VERSION "dbc-export 1 2025.20.8"

NS_ :

BS_:

BU_: CC EPBR GTW HVP PCS VCFRONT VCRIGHT VCSEC

BO_ 812 CC_logData: 8 CC
 SG_ CC_logIndex M : 0|8@1+ (1,0) [0|255] "" Vector__XXX
 SG_ CC_activeConnectorID m0 : 8|8@1+ (1,0) [0|255] "" Vector__XXX
 SG_ CC_temperature1 m0 : 16|8@1- (1,88) [-40|215] "DegC" Vector__XXX
 SG_ CC_temperature2 m0 : 24|8@1- (1,88) [-40|215] "DegC" Vector__XXX
 SG_ CC_temperature3 m0 : 32|8@1- (1,88) [-40|215] "DegC" Vector__XXX
 SG_ CC_contactor1Closed m0 : 40|2@1+ (1,0) [0|3] "" Vector__XXX
 SG_ CC_contactor2Closed m0 : 42|2@1+ (1,0) [0|3] "" Vector__XXX
 SG_ CC_temperature4 m0 : 44|8@1- (1,88) [-40|215] "DegC" Vector__XXX
 SG_ CC_conn1Current m1 : 8|8@1+ (0.5,0) [0|127] "A" Vector__XXX
 SG_ CC_conn2Current m2 : 8|8@1+ (0.5,0) [0|127] "A" Vector__XXX
 SG_ CC_conn3Current m3 : 8|8@1+ (0.5,0) [0|127] "A" Vector__XXX
 SG_ CC_conn4Current m4 : 8|8@1+ (0.5,0) [0|127] "A" Vector__XXX
 SG_ CC_lifetimei2t m10 : 32|32@1+ (0.1,0) [0|429496729.5] "A2h" Vector__XXX
 SG_ CC_lifetimeCtrCycles m11 : 8|28@1+ (1,0) [0|268435455] "" Vector__XXX
 SG_ CC_lifetimeCtrCyclesLoaded m11 : 36|28@1+ (1,0) [0|268435455] "" Vector__XXX
 SG_ CC_lifetimeAlertCount m12 : 8|28@1+ (1,0) [0|268435455] "" Vector__XXX
 SG_ CC_lifetimeThermalFoldbacks m12 : 36|28@1+ (1,0) [0|268435455] "" Vector__XXX
 SG_ CC_lifetimeAvgStartupTemp m13 : 36|28@1- (0.1,0) [-13421772.8|13421772.7] "degC" Vector__XXX

BO_ 2024 EPBR_info: 8 EPBR
 SG_ EPBR_infoIndex M : 0|8@1+ (1,0) [0|255] "" Vector__XXX
 SG_ EPBR_infoBuildType m10 : 8|3@1+ (1,0) [0|7] "" Vector__XXX
 SG_ EPBR_infoBuildConfigId m10 : 16|16@1+ (1,0) [0|65535] "" Vector__XXX
 SG_ EPBR_infoHardwareId m10 : 32|16@1+ (1,0) [0|65535] "" Vector__XXX
 SG_ EPBR_infoComponentId m10 : 48|16@1+ (1,0) [0|65535] "" Vector__XXX
 SG_ EPBR_infoPcbaId m11 : 8|8@1+ (1,0) [0|255] "" Vector__XXX
 SG_ EPBR_infoAssemblyId m11 : 16|8@1+ (1,0) [0|254] "" Vector__XXX
 SG_ EPBR_infoUsageId m11 : 24|16@1+ (1,0) [0|65535] "" Vector__XXX
 SG_ EPBR_infoSubUsageId m11 : 40|16@1+ (1,0) [0|65535] "" Vector__XXX
 SG_ EPBR_infoAppCrc m13 : 8|32@1+ (1,0) [0|4294967295] "" Vector__XXX
 SG_ EPBR_infoAppGitHash m17 : 8|56@1+ (1,0) [0|7.20575940379e+16] "" Vector__XXX
 SG_ EPBR_infoBootGitHash m18 : 8|56@1+ (1,0) [0|7.20575940379e+16] "" Vector__XXX
 SG_ EPBR_infoPlatformType m19 : 8|8@1+ (1,0) [0|255] "" Vector__XXX
 SG_ EPBR_infoBootUdsProtoVersion m20 : 8|16@1+ (1,0) [0|65535] "" Vector__XXX
 SG_ EPBR_infoBootCrc m20 : 24|32@1+ (1,0) [0|4294967295] "" Vector__XXX

BO_ 1914 HVP_log1hz: 8 HVP
 SG_ HVP_log1HzIndex M : 0|3@1+ (1,0) [0|7] "" Vector__XXX
 SG_ HVP_bmbAsicType m0 : 3|2@1+ (1,0) [0|3] "" Vector__XXX
 SG_ HVP_shuntCurrentAuxLog m0 : 8|24@1- (0.001,0) [-8388.607|8388.607] "A" Vector__XXX
 SG_ HVP_pyroSquibResistance m0 : 32|16@1+ (0.001,0) [0|65.534] "Ohm" Vector__XXX
 SG_ HVP_shuntAsicChipXCoordinate m0 : 48|8@1+ (1,0) [0|255] "" Vector__XXX
 SG_ HVP_shuntAsicChipYCoordinate m0 : 56|8@1+ (1,0) [0|255] "" Vector__XXX
 SG_ HVP_hvilCalType m1 : 3|2@1+ (1,0) [0|3] "" Vector__XXX
 SG_ HVP_gpioPcsDcdcPwmEnable m1 : 5|1@1+ (1,0) [0|1] "" Vector__XXX
 SG_ HVP_gpioPcsChargePwmEnable m1 : 6|1@1+ (1,0) [0|1] "" Vector__XXX
 SG_ HVP_gpioPcsEnable m1 : 7|1@1+ (1,0) [0|1] "" Vector__XXX
 SG_ HVP_shuntAsicChipWaferNumber m1 : 8|8@1+ (1,0) [0|255] "" Vector__XXX
 SG_ HVP_energyReserveMin m1 : 16|16@1- (0.001,0) [-32.768|32.767] "V" Vector__XXX
 SG_ HVP_energyReserveMax m1 : 32|16@1- (0.001,0) [-32.768|32.767] "V" Vector__XXX
 SG_ HVP_energyReserveAvg m1 : 48|16@1- (0.001,0) [-32.768|32.767] "V" Vector__XXX

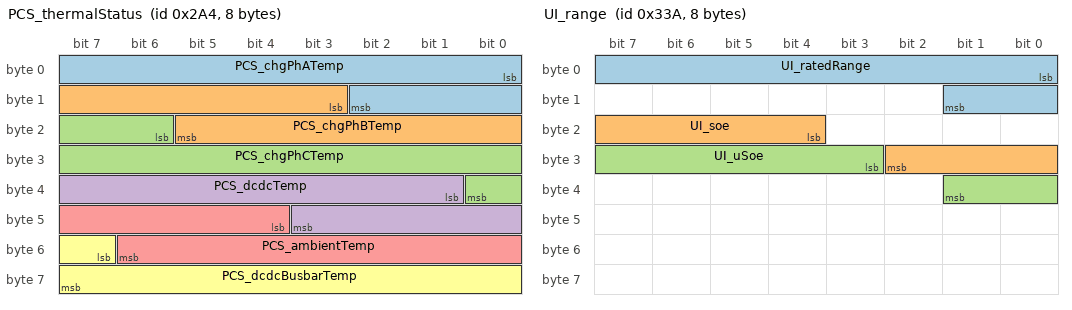
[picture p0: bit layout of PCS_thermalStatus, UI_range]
BO_ 676 PCS_thermalStatus: 8 PCS
 SG_ PCS_chgPhATemp : 0|11@1- (0.1,40) [-62.4|142.3] "C" Vector__XXX
 SG_ PCS_chgPhBTemp : 11|11@1- (0.1,40) [-62.4|142.3] "C" Vector__XXX
 SG_ PCS_chgPhCTemp : 22|11@1- (0.1,40) [-62.4|142.3] "C" Vector__XXX
 SG_ PCS_dcdcTemp : 33|11@1- (0.1,40) [-62.4|142.3] "C" Vector__XXX
 SG_ PCS_ambientTemp : 44|11@1- (0.1,40) [-62.4|142.3] "C" Vector__XXX
 SG_ PCS_dcdcBusbarTemp : 55|9@1+ (0.2935421,0) [0|149.706471] "C" Vector__XXX

BO_ 826 UI_range: 8 GTW
 SG_ UI_ratedRange : 0|10@1+ (1,0) [0|1023] "mi" Vector__XXX
 SG_ UI_soe : 20|7@1+ (1,0) [0|127] "%" Vector__XXX
 SG_ UI_uSoe : 27|7@1+ (1,0) [0|127] "%" Vector__XXX

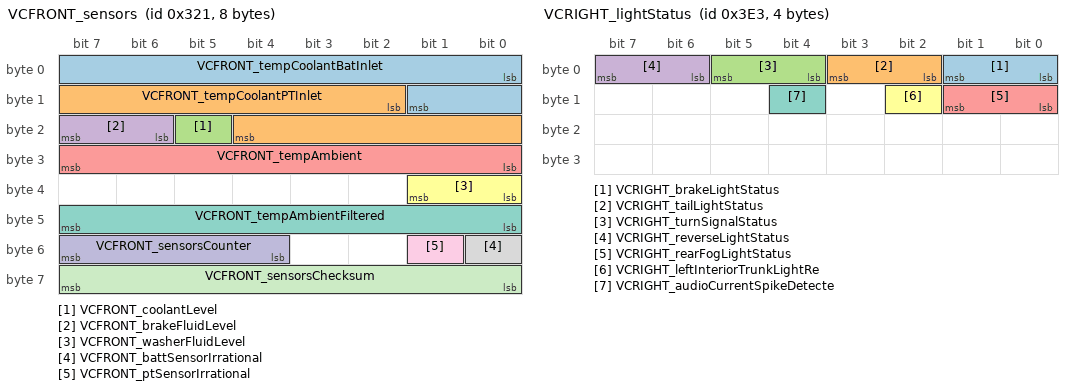
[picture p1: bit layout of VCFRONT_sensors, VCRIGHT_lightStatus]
BO_ 801 VCFRONT_sensors: 8 VCFRONT
 SG_ VCFRONT_tempCoolantBatInlet : 0|10@1+ (0.125,-40) [-40|85] "degC" Vector__XXX
 SG_ VCFRONT_tempCoolantPTInlet : 10|11@1+ (0.125,-40) [-40|200] "degC" Vector__XXX
 SG_ VCFRONT_coolantLevel : 21|1@1+ (1,0) [0|1] "" Vector__XXX
 SG_ VCFRONT_brakeFluidLevel : 22|2@1+ (1,0) [1|3] "" Vector__XXX
 SG_ VCFRONT_tempAmbient : 24|8@1+ (0.5,-40) [-39.5|80] "degC" Vector__XXX
 SG_ VCFRONT_washerFluidLevel : 32|2@1+ (1,0) [1|3] "" Vector__XXX
 SG_ VCFRONT_tempAmbientFiltered : 40|8@1+ (0.5,-40) [-39.5|80] "degC" Vector__XXX
 SG_ VCFRONT_battSensorIrrational : 48|1@1+ (1,0) [0|1] "" Vector__XXX
 SG_ VCFRONT_ptSensorIrrational : 49|1@1+ (1,0) [0|1] "" Vector__XXX
 SG_ VCFRONT_sensorsCounter : 52|4@1+ (1,0) [0|15] "" Vector__XXX
 SG_ VCFRONT_sensorsChecksum : 56|8@1+ (1,0) [0|255] "" Vector__XXX

BO_ 1349 VCFRONT_systemStatus: 8 VCFRONT
 SG_ VCFRONT_systemStatusMuxIndex M : 0|2@1+ (1,0) [0|3] "" Vector__XXX
 SG_ VCFRONT_systemStatusCounter : 52|4@1+ (1,0) [0|15] "" Vector__XXX
 SG_ VCFRONT_systemStatusChecksum : 56|8@1+ (1,0) [0|255] "" Vector__XXX
 SG_ VCFRONT_loadShedReason m1 : 3|9@1+ (1,0) [0|511] "" Vector__XXX
 SG_ VCFRONT_VCRightEFuseLoadShedStag m1 : 12|5@1+ (1,0) [0|31] "" Vector__XXX
 SG_ VCFRONT_VCLeftEFuseLoadShedStage m1 : 20|5@1+ (1,0) [0|31] "" Vector__XXX
 SG_ VCFRONT_DCDCSaturationLoadShedSt m1 : 28|5@1+ (1,0) [0|31] "" Vector__XXX
 SG_ VCFRONT_vehicleLoadShedStage m1 : 36|2@1+ (1,0) [0|3] "" Vector__XXX
 SG_ VCFRONT_HVFaultVehicleLoadShedRe m1 : 38|1@1+ (1,0) [0|1] "" Vector__XXX
 SG_ VCFRONT_postCrashVehicleLoadShed m1 : 39|1@1+ (1,0) [0|1] "" Vector__XXX
 SG_ VCFRONT_HVFaultVehicleLoadShedAc m1 : 40|1@1+ (1,0) [0|1] "" Vector__XXX
 SG_ VCFRONT_factoryVehicleLoadShedAc m1 : 41|1@1+ (1,0) [0|1] "" Vector__XXX
 SG_ VCFRONT_anyVehicleLoadShedActive m1 : 42|1@1+ (1,0) [0|1] "" Vector__XXX
 SG_ VCFRONT_DIVehLoadShedActive m1 : 43|1@1+ (1,0) [0|1] "" Vector__XXX
 SG_ VCFRONT_HVFaultLoadShedStateDBG m1 : 44|2@1+ (1,0) [0|3] "" Vector__XXX
 SG_ VCFRONT_LVUnhealthyVehicleLoadSh m1 : 46|1@1+ (1,0) [0|1] "" Vector__XXX
 SG_ VCFRONT_loadShedStsCondenserFan m2 : 3|1@1+ (1,0) [0|1] "" Vector__XXX
 SG_ VCFRONT_loadShedStsPTPump m2 : 6|1@1+ (1,0) [0|1] "" Vector__XXX
 SG_ VCFRONT_loadShedMCUAudio m2 : 10|1@1+ (1,0) [0|1] "" Vector__XXX
 SG_ VCFRONT_loadShedHVDownTriggerDBG m2 : 11|1@1+ (1,0) [0|1] "" Vector__XXX
 SG_ VCFRONT_loadShedPCSSatTriggerDBG m2 : 12|1@1+ (1,0) [0|1] "" Vector__XXX
 SG_ VCFRONT_loadShedStsBatteryPump m2 : 13|1@1+ (1,0) [0|1] "" Vector__XXX
 SG_ VCFRONT_loadShedStsAPGlassHeater m2 : 14|1@1+ (1,0) [0|1] "" Vector__XXX
 SG_ VCFRONT_loadShedStsMCUGraphics m2 : 15|1@1+ (1,0) [0|1] "" Vector__XXX
 SG_ VCFRONT_IBSCurrentRMS_loadShed m2 : 16|7@1+ (0.05,0) [0|6.35] "A" Vector__XXX
 SG_ VCFRONT_loadShedAhLeakyBktCntDBG m2 : 23|9@1+ (0.001,0) [0|0.511] "Ah" Vector__XXX
 SG_ VCFRONT_loadShedPcs m2 : 33|1@1+ (1,0) [0|1] "" Vector__XXX
 SG_ VCFRONT_loadShedGTWDownstrmRails m2 : 35|1@1+ (1,0) [0|1] "" Vector__XXX
 SG_ VCFRONT_loadShedPCSMIATriggerDBG m2 : 36|1@1+ (1,0) [0|1] "" Vector__XXX
 SG_ VCFRONT_loadShedTAS m2 : 37|1@1+ (1,0) [0|1] "" Vector__XXX
 SG_ VCFRONT_loadShedBackStopBktCntDB m2 : 38|5@1+ (0.05,0) [0|1.55] "Ah" Vector__XXX
 SG_ VCFRONT_loadShedPCSLeakyBktCtDBG m2 : 44|6@1+ (100,0) [0|6300] "mV" Vector__XXX
 SG_ VCFRONT_loadShedUI m2 : 50|1@1+ (1,0) [0|1] "" Vector__XXX
 SG_ VCFRONT_loadShedAutoPilot m2 : 51|1@1+ (1,0) [0|1] "" Vector__XXX

BO_ 995 VCRIGHT_lightStatus: 4 VCRIGHT
 SG_ VCRIGHT_brakeLightStatus : 0|2@1+ (1,0) [0|2] "" Vector__XXX
 SG_ VCRIGHT_tailLightStatus : 2|2@1+ (1,0) [0|2] "" Vector__XXX
 SG_ VCRIGHT_turnSignalStatus : 4|2@1+ (1,0) [0|2] "" Vector__XXX
 SG_ VCRIGHT_reverseLightStatus : 6|2@1+ (1,0) [0|2] "" Vector__XXX
 SG_ VCRIGHT_rearFogLightStatus : 8|2@1+ (1,0) [0|2] "" Vector__XXX
 SG_ VCRIGHT_leftInteriorTrunkLightRe : 10|1@1+ (1,0) [0|1] "" Vector__XXX
 SG_ VCRIGHT_audioCurrentSpikeDetecte : 12|1@1+ (1,0) [0|1] "" Vector__XXX

BO_ 1066 VCSEC_TPMSConnectionData: 8 VCSEC
 SG_ VCSEC_TPMSSensorState0 : 0|3@1+ (1,0) [0|7] "" Vector__XXX
 SG_ VCSEC_TPMSRSSI0 : 3|7@1+ (1,-127) [-127|0] "dBm" Vector__XXX
 SG_ VCSEC_TPMSConnectionTypeCurrent0 : 10|2@1+ (1,0) [0|3] "" Vector__XXX
 SG_ VCSEC_TPMSConnectionTypeDesired0 : 12|2@1+ (1,0) [0|3] "" Vector__XXX
 SG_ VCSEC_TPMSSensorState1 : 14|3@1+ (1,0) [0|7] "" Vector__XXX
 SG_ VCSEC_TPMSRSSI1 : 17|7@1+ (1,-127) [-127|0] "dBm" Vector__XXX
 SG_ VCSEC_TPMSConnectionTypeCurrent1 : 24|2@1+ (1,0) [0|3] "" Vector__XXX
 SG_ VCSEC_TPMSConnectionTypeDesired1 : 26|2@1+ (1,0) [0|3] "" Vector__XXX
 SG_ VCSEC_TPMSSensorState2 : 28|3@1+ (1,0) [0|7] "" Vector__XXX
 SG_ VCSEC_TPMSRSSI2 : 31|7@1+ (1,-127) [-127|0] "dBm" Vector__XXX
 SG_ VCSEC_TPMSConnectionTypeCurrent2 : 38|2@1+ (1,0) [0|3] "" Vector__XXX
 SG_ VCSEC_TPMSConnectionTypeDesired2 : 40|2@1+ (1,0) [0|3] "" Vector__XXX
 SG_ VCSEC_TPMSSensorState3 : 42|3@1+ (1,0) [0|7] "" Vector__XXX
 SG_ VCSEC_TPMSRSSI3 : 45|7@1+ (1,-127) [-127|0] "dBm" Vector__XXX
 SG_ VCSEC_TPMSConnectionTypeCurrent3 : 52|2@1+ (1,0) [0|3] "" Vector__XXX
 SG_ VCSEC_TPMSConnectionTypeDesired3 : 54|2@1+ (1,0) [0|3] "" Vector__XXX
 SG_ VCSEC_TPMSSensorPresence0 : 56|2@1+ (1,0) [0|3] "" Vector__XXX
 SG_ VCSEC_TPMSSensorPresence1 : 58|2@1+ (1,0) [0|3] "" Vector__XXX
 SG_ VCSEC_TPMSSensorPresence2 : 60|2@1+ (1,0) [0|3] "" Vector__XXX
 SG_ VCSEC_TPMSSensorPresence3 : 62|2@1+ (1,0) [0|3] "" Vector__XXX

BO_TX_BU_ 812 : CC;
BO_TX_BU_ 2024 : EPBR;
BO_TX_BU_ 1914 : HVP;
BO_TX_BU_ 676 : PCS;
BO_TX_BU_ 826 : GTW;
BO_TX_BU_ 801 : VCFRONT;
BO_TX_BU_ 1349 : VCFRONT;
BO_TX_BU_ 995 : VCRIGHT;
BO_TX_BU_ 1066 : VCSEC;

CM_ "Tesla Bayberry CAN bus database; bus VEH (vehicle CAN); firmware 2025.20.8. Decoded CAN signal definitions (layout, scaling, units, value tables).";
CM_ BU_ CC "Charge cable controller";
CM_ BU_ EPBR "Right electric parking brake";
CM_ BU_ GTW "Gateway";
CM_ BU_ HVP "High-voltage processor (pack contactor and isolation controller)";
CM_ BU_ PCS "Power conversion system (on-board charger and DC-DC converter)";
CM_ BU_ VCFRONT "Front body controller";
CM_ BU_ VCRIGHT "Right body controller";
CM_ BU_ VCSEC "Vehicle security controller";
CM_ BO_ 812 "Charge cable controller message: log data; frame length from the layout, not yet observed on a vehicle bus";
CM_ SG_ 812 CC_logIndex "Charge cable controller: log index";
CM_ SG_ 812 CC_activeConnectorID "Site identifier of active charge connector";
CM_ SG_ 812 CC_temperature1 "Charge cable vehicle connector temperature";
CM_ SG_ 812 CC_temperature2 "Charge cable vehicle connector temperature";
CM_ SG_ 812 CC_temperature3 "Charge cable vehicle connector temperature";
CM_ SG_ 812 CC_contactor1Closed "State of contactor 1 in wall connector";
CM_ SG_ 812 CC_contactor2Closed "State of contactor 1 in wall connector";
CM_ SG_ 812 CC_temperature4 "Charge cable vehicle connector temperature";
CM_ SG_ 812 CC_conn1Current "AC current on connector 1 in wall charger load sharing group; raw 255 = signal not available (SNA)";
CM_ SG_ 812 CC_conn2Current "AC current on connector 2 in wall charger load sharing group; raw 255 = signal not available (SNA)";
CM_ SG_ 812 CC_conn3Current "AC current on connector 3 in wall charger load sharing group; raw 255 = signal not available (SNA)";
CM_ SG_ 812 CC_conn4Current "AC current on connector 4 in wall charger load sharing group; raw 255 = signal not available (SNA)";
CM_ SG_ 812 CC_lifetimei2t "Charge cable controller: lifetimei2t";
CM_ SG_ 812 CC_lifetimeCtrCycles "Charge cable controller: lifetime ctr cycles";
CM_ SG_ 812 CC_lifetimeCtrCyclesLoaded "Charge cable controller: lifetime ctr cycles loaded";
CM_ SG_ 812 CC_lifetimeAlertCount "Charge cable controller: lifetime alert count";
CM_ SG_ 812 CC_lifetimeThermalFoldbacks "Charge cable controller: lifetime thermal foldbacks";
CM_ SG_ 812 CC_lifetimeAvgStartupTemp "Charge cable controller: lifetime avg startup temp";
CM_ BO_ 2024 "Right electric parking brake message: info; frame length observed on a vehicle bus";
CM_ SG_ 2024 EPBR_infoIndex "Right electric parking brake: info index";
CM_ SG_ 2024 EPBR_infoBuildType "Right electric parking brake: info build type";
CM_ SG_ 2024 EPBR_infoBuildConfigId "Right electric parking brake: info build config id";
CM_ SG_ 2024 EPBR_infoHardwareId "Right electric parking brake: info hardware id";
CM_ SG_ 2024 EPBR_infoComponentId "Right electric parking brake: info component id";
CM_ SG_ 2024 EPBR_infoPcbaId "Right electric parking brake: info pcba id";
CM_ SG_ 2024 EPBR_infoAssemblyId "Right electric parking brake: info assembly id; raw 255 = signal not available (SNA)";
CM_ SG_ 2024 EPBR_infoUsageId "Right electric parking brake: info usage id";
CM_ SG_ 2024 EPBR_infoSubUsageId "Right electric parking brake: info sub usage id";
CM_ SG_ 2024 EPBR_infoAppCrc "Right electric parking brake: info app crc";
CM_ SG_ 2024 EPBR_infoAppGitHash "Right electric parking brake: info app git hash";
CM_ SG_ 2024 EPBR_infoBootGitHash "Right electric parking brake: info boot git hash";
CM_ SG_ 2024 EPBR_infoPlatformType "Right electric parking brake: info platform type";
CM_ SG_ 2024 EPBR_infoBootUdsProtoVersion "Right electric parking brake: info boot uds proto version";
CM_ SG_ 2024 EPBR_infoBootCrc "Right electric parking brake: info boot crc";
CM_ BO_ 1914 "High-voltage processor (pack contactor and isolation controller) message: log1hz; frame length observed on a vehicle bus";
CM_ SG_ 1914 HVP_log1HzIndex "High-voltage processor (pack contactor and isolation controller): log1 hz index";
CM_ SG_ 1914 HVP_bmbAsicType "The BMB Asic type being used by this battery pack for reading brick data";
CM_ SG_ 1914 HVP_shuntCurrentAuxLog "High-voltage processor (pack contactor and isolation controller): shunt current aux log";
CM_ SG_ 1914 HVP_pyroSquibResistance "The pyro resistance measured on attempt to close contactor or by the Pyro selftest; raw 65535 = signal not available (SNA)";
CM_ SG_ 1914 HVP_shuntAsicChipXCoordinate "High-voltage processor (pack contactor and isolation controller): shunt asic chip x coordinate";
CM_ SG_ 1914 HVP_shuntAsicChipYCoordinate "High-voltage processor (pack contactor and isolation controller): shunt asic chip y coordinate";
CM_ SG_ 1914 HVP_hvilCalType "High-voltage processor (pack contactor and isolation controller): hvil cal type";
CM_ SG_ 1914 HVP_gpioPcsDcdcPwmEnable "High-voltage processor (pack contactor and isolation controller): gpio pcs dcdc pwm enable";
CM_ SG_ 1914 HVP_gpioPcsChargePwmEnable "High-voltage processor (pack contactor and isolation controller): gpio pcs charge pwm enable";
CM_ SG_ 1914 HVP_gpioPcsEnable "HVP GPIO control for PCS logic power enable line";
CM_ SG_ 1914 HVP_shuntAsicChipWaferNumber "High-voltage processor (pack contactor and isolation controller): shunt asic chip wafer number";
CM_ SG_ 1914 HVP_energyReserveMin "a lowest energy reserve value measured over sliding window";
CM_ SG_ 1914 HVP_energyReserveMax "a highest energy reserve value measured over sliding window";
CM_ SG_ 1914 HVP_energyReserveAvg "an average energy reserve value measured over sliding window";
CM_ BO_ 676 "Power conversion system (on-board charger and DC-DC converter) message: thermal status; frame length observed on a vehicle bus";
CM_ SG_ 676 PCS_chgPhATemp "Sensed temperature of AC charger phase A; raw 1025 = signal not available (SNA)";
CM_ SG_ 676 PCS_chgPhBTemp "Sensed temperature of AC charger phase B; raw 1025 = signal not available (SNA)";
CM_ SG_ 676 PCS_chgPhCTemp "Sensed temperature of AC charger phase C; raw 1025 = signal not available (SNA)";
CM_ SG_ 676 PCS_dcdcTemp "Sensed temperature of DCDC; raw 1025 = signal not available (SNA)";
CM_ SG_ 676 PCS_ambientTemp "Ambient temperature sensed by the PCS; raw 1025 = signal not available (SNA)";
CM_ SG_ 676 PCS_dcdcBusbarTemp "Sensed temperature of DCDC busbar; raw 511 = signal not available (SNA)";
CM_ BO_ 826 "Touchscreen user interface computer message: range; forwarded onto this bus by the gateway; frame length observed on a vehicle bus";
CM_ SG_ 826 UI_ratedRange "Rated range in miles";
CM_ SG_ 826 UI_soe "State of energy";
CM_ SG_ 826 UI_uSoe "Usable state of energy";
CM_ BO_ 801 "Front body controller message: sensors; frame length observed on a vehicle bus";
CM_ SG_ 801 VCFRONT_tempCoolantBatInlet "Battery measured inlet coolant temperature; raw 1023 = signal not available (SNA)";
CM_ SG_ 801 VCFRONT_tempCoolantPTInlet "Powertrain measured inlet coolant temperature; raw 2047 = signal not available (SNA)";
CM_ SG_ 801 VCFRONT_coolantLevel "Front body controller: coolant level";
CM_ SG_ 801 VCFRONT_brakeFluidLevel "Reports detected brake fluid level at the fluid reservoir; raw 0 = signal not available (SNA)";
CM_ SG_ 801 VCFRONT_tempAmbient "Front body controller: temp ambient; raw 0 = signal not available (SNA)";
CM_ SG_ 801 VCFRONT_washerFluidLevel "Indicates that the sensor has detected low windshield washer fluid; raw 0 = signal not available (SNA)";
CM_ SG_ 801 VCFRONT_tempAmbientFiltered "Filtered ambient temperature based on vehicle speed; raw 0 = signal not available (SNA)";
CM_ SG_ 801 VCFRONT_battSensorIrrational "Front body controller: batt sensor irrational";
CM_ SG_ 801 VCFRONT_ptSensorIrrational "Front body controller: pt sensor irrational";
CM_ SG_ 801 VCFRONT_sensorsCounter "Front body controller: sensors counter";
CM_ SG_ 801 VCFRONT_sensorsChecksum "Front body controller: sensors checksum";
CM_ BO_ 1349 "Front body controller message: system status; frame length observed on a vehicle bus";
CM_ SG_ 1349 VCFRONT_systemStatusMuxIndex "Front body controller: system status mux index";
CM_ SG_ 1349 VCFRONT_systemStatusCounter "Front body controller: system status counter";
CM_ SG_ 1349 VCFRONT_systemStatusChecksum "Front body controller: system status checksum";
CM_ SG_ 1349 VCFRONT_loadShedReason "Front body controller: load shed reason";
CM_ SG_ 1349 VCFRONT_VCRightEFuseLoadShedStag "Front body controller: VC right e fuse load shed stage";
CM_ SG_ 1349 VCFRONT_VCLeftEFuseLoadShedStage "Front body controller: VC left e fuse load shed stage";
CM_ SG_ 1349 VCFRONT_DCDCSaturationLoadShedSt "Front body controller: DCDC saturation load shed stage";
CM_ SG_ 1349 VCFRONT_vehicleLoadShedStage "Front body controller: vehicle load shed stage";
CM_ SG_ 1349 VCFRONT_HVFaultVehicleLoadShedRe "Front body controller: HV fault vehicle load shed request";
CM_ SG_ 1349 VCFRONT_postCrashVehicleLoadShed "Front body controller: post crash vehicle load shed active";
CM_ SG_ 1349 VCFRONT_HVFaultVehicleLoadShedAc "Front body controller: HV fault vehicle load shed active";
CM_ SG_ 1349 VCFRONT_factoryVehicleLoadShedAc "Indicates that vehicle is factory load shedding";
CM_ SG_ 1349 VCFRONT_anyVehicleLoadShedActive "Front body controller: any vehicle load shed active";
CM_ SG_ 1349 VCFRONT_DIVehLoadShedActive "Front body controller: DI veh load shed active";
CM_ SG_ 1349 VCFRONT_HVFaultLoadShedStateDBG "Front body controller: HV fault load shed state DBG";
CM_ SG_ 1349 VCFRONT_LVUnhealthyVehicleLoadSh "Front body controller: LV unhealthy vehicle load shed active";
CM_ SG_ 1349 VCFRONT_loadShedStsCondenserFan "Front body controller: load shed sts condenser fan";
CM_ SG_ 1349 VCFRONT_loadShedStsPTPump "Front body controller: load shed sts PT pump";
CM_ SG_ 1349 VCFRONT_loadShedMCUAudio "Front body controller: load shed MCU audio";
CM_ SG_ 1349 VCFRONT_loadShedHVDownTriggerDBG "Front body controller: load shed HV down trigger DBG";
CM_ SG_ 1349 VCFRONT_loadShedPCSSatTriggerDBG "Front body controller: load shed PCS sat trigger DBG";
CM_ SG_ 1349 VCFRONT_loadShedStsBatteryPump "Front body controller: load shed sts battery pump";
CM_ SG_ 1349 VCFRONT_loadShedStsAPGlassHeater "Front body controller: load shed sts AP glass heater";
CM_ SG_ 1349 VCFRONT_loadShedStsMCUGraphics "Front body controller: load shed sts MCU graphics";
CM_ SG_ 1349 VCFRONT_IBSCurrentRMS_loadShed "Front body controller: IBS current RMS load shed";
CM_ SG_ 1349 VCFRONT_loadShedAhLeakyBktCntDBG "Front body controller: load shed ah leaky bkt cnt DBG";
CM_ SG_ 1349 VCFRONT_loadShedPcs "Front body controller: load shed pcs";
CM_ SG_ 1349 VCFRONT_loadShedGTWDownstrmRails "Front body controller: load shed GTW downstrm rails";
CM_ SG_ 1349 VCFRONT_loadShedPCSMIATriggerDBG "Front body controller: load shed PCSMIA trigger DBG";
CM_ SG_ 1349 VCFRONT_loadShedTAS "Front body controller: load shed TAS";
CM_ SG_ 1349 VCFRONT_loadShedBackStopBktCntDB "Front body controller: load shed back stop bkt cnt DBG";
CM_ SG_ 1349 VCFRONT_loadShedPCSLeakyBktCtDBG "Front body controller: load shed PCS leaky bkt ct DBG";
CM_ SG_ 1349 VCFRONT_loadShedUI "Front body controller: load shed UI";
CM_ SG_ 1349 VCFRONT_loadShedAutoPilot "Front body controller: load shed auto pilot";
CM_ BO_ 995 "Right body controller message: light status; frame length observed on a vehicle bus";
CM_ SG_ 995 VCRIGHT_brakeLightStatus "Status of rear right brake light source; raw 3 = signal not available (SNA)";
CM_ SG_ 995 VCRIGHT_tailLightStatus "Status of right tail (rear position) light source; raw 3 = signal not available (SNA)";
CM_ SG_ 995 VCRIGHT_turnSignalStatus "Status of rear right turn signal light source; raw 3 = signal not available (SNA)";
CM_ SG_ 995 VCRIGHT_reverseLightStatus "Status of the reverse light source(s); raw 3 = signal not available (SNA)";
CM_ SG_ 995 VCRIGHT_rearFogLightStatus "The desired on/off state of the rear fog light source(s); raw 3 = signal not available (SNA)";
CM_ SG_ 995 VCRIGHT_leftInteriorTrunkLightRe "Right body controller: left interior trunk light req";
CM_ SG_ 995 VCRIGHT_audioCurrentSpikeDetecte "Right body controller: audio current spike detected";
CM_ BO_ 1066 "Vehicle security controller message: TPMS connection data; frame length from the layout, not yet observed on a vehicle bus";
CM_ SG_ 1066 VCSEC_TPMSSensorState0 "Indicates the sensors pairing/connectivity status";
CM_ SG_ 1066 VCSEC_TPMSRSSI0 "Received Signal Strength Index reported by sensor.";
CM_ SG_ 1066 VCSEC_TPMSConnectionTypeCurrent0 "Vehicle security controller: TPMS connection type current0";
CM_ SG_ 1066 VCSEC_TPMSConnectionTypeDesired0 "Vehicle security controller: TPMS connection type desired0";
CM_ SG_ 1066 VCSEC_TPMSSensorState1 "Indicates the sensors pairing/connectivity status";
CM_ SG_ 1066 VCSEC_TPMSRSSI1 "Received Signal Strength Index reported by sensor.";
CM_ SG_ 1066 VCSEC_TPMSConnectionTypeCurrent1 "Vehicle security controller: TPMS connection type current1";
CM_ SG_ 1066 VCSEC_TPMSConnectionTypeDesired1 "Vehicle security controller: TPMS connection type desired1";
CM_ SG_ 1066 VCSEC_TPMSSensorState2 "Indicates the sensors pairing/connectivity status";
CM_ SG_ 1066 VCSEC_TPMSRSSI2 "Received Signal Strength Index reported by sensor.";
CM_ SG_ 1066 VCSEC_TPMSConnectionTypeCurrent2 "Vehicle security controller: TPMS connection type current2";
CM_ SG_ 1066 VCSEC_TPMSConnectionTypeDesired2 "Vehicle security controller: TPMS connection type desired2";
CM_ SG_ 1066 VCSEC_TPMSSensorState3 "Indicates the sensors pairing/connectivity status";
CM_ SG_ 1066 VCSEC_TPMSRSSI3 "Received Signal Strength Index reported by sensor.";
CM_ SG_ 1066 VCSEC_TPMSConnectionTypeCurrent3 "Vehicle security controller: TPMS connection type current3";
CM_ SG_ 1066 VCSEC_TPMSConnectionTypeDesired3 "Vehicle security controller: TPMS connection type desired3";
CM_ SG_ 1066 VCSEC_TPMSSensorPresence0 "Indicates the sensors detection status";
CM_ SG_ 1066 VCSEC_TPMSSensorPresence1 "Indicates the sensors detection status";
CM_ SG_ 1066 VCSEC_TPMSSensorPresence2 "Indicates the sensors detection status";
CM_ SG_ 1066 VCSEC_TPMSSensorPresence3 "Indicates the sensors detection status";
BA_DEF_ "BusType" STRING;
BA_DEF_ "DBName" STRING;
BA_DEF_ "Baudrate" INT 0 1000000;
BA_DEF_ "BaudrateCANFD" INT 0 16000000;
BA_DEF_ "Manufacturer" STRING;
BA_DEF_ "FirmwareVersion" STRING;
BA_DEF_ "VehicleModel" STRING;
BA_DEF_ BU_ "ECU" STRING;
BA_DEF_ BO_ "GenMsgCycleTime" INT 0 3600000;
BA_DEF_ BO_ "GenMsgSendType" ENUM "Cyclic","NotUsed","NotUsed","NotUsed","NotUsed","NotUsed","NotUsed","IfActive","NoMsgSendType","NotUsed";
BA_DEF_ BO_ "VFrameFormat" ENUM "StandardCAN","ExtendedCAN","reserved","J1939PG","reserved","reserved","reserved","reserved","reserved","reserved","reserved","reserved","reserved","reserved","StandardCAN_FD","ExtendedCAN_FD";
BA_DEF_ BO_ "CANFD_BRS" ENUM "0","1";
BA_DEF_ SG_ "GenSigSNA" STRING;
BA_DEF_ SG_ "SystemSignalLongSymbol" STRING;
BA_DEF_ SG_ "Confidence" ENUM "validated","plausible","layout-only","contradicted";
BA_DEF_DEF_ "BusType" "CAN";
BA_DEF_DEF_ "DBName" "";
BA_DEF_DEF_ "Baudrate" 500000;
BA_DEF_DEF_ "BaudrateCANFD" 2000000;
BA_DEF_DEF_ "Manufacturer" "";
BA_DEF_DEF_ "FirmwareVersion" "";
BA_DEF_DEF_ "VehicleModel" "";
BA_DEF_DEF_ "ECU" "";
BA_DEF_DEF_ "GenMsgCycleTime" 0;
BA_DEF_DEF_ "GenMsgSendType" "NoMsgSendType";
BA_DEF_DEF_ "VFrameFormat" "StandardCAN";
BA_DEF_DEF_ "CANFD_BRS" "1";
BA_DEF_DEF_ "GenSigSNA" "";
BA_DEF_DEF_ "SystemSignalLongSymbol" "";
BA_DEF_DEF_ "Confidence" "layout-only";
BA_ "DBName" "Bayberry_VEH";
BA_ "Manufacturer" "Tesla";
BA_ "FirmwareVersion" "2025.20.8";
BA_ "VehicleModel" "Bayberry";
BA_ "ECU" BU_ CC "CC";
BA_ "ECU" BU_ EPBR "EPBR";
BA_ "ECU" BU_ GTW "GTW";
BA_ "ECU" BU_ HVP "HVP";
BA_ "ECU" BU_ PCS "PCS";
BA_ "ECU" BU_ VCFRONT "VCFRONT";
BA_ "ECU" BU_ VCRIGHT "VCRIGHT";
BA_ "ECU" BU_ VCSEC "VCSEC";
BA_ "GenMsgCycleTime" BO_ 812 1000;
BA_ "GenMsgSendType" BO_ 812 0;
BA_ "GenMsgCycleTime" BO_ 2024 1000;
BA_ "GenMsgSendType" BO_ 2024 0;
BA_ "GenMsgCycleTime" BO_ 1914 1000;
BA_ "GenMsgSendType" BO_ 1914 0;
BA_ "GenMsgCycleTime" BO_ 676 1000;
BA_ "GenMsgSendType" BO_ 676 0;
BA_ "GenMsgCycleTime" BO_ 826 1000;
BA_ "GenMsgSendType" BO_ 826 0;
BA_ "GenMsgCycleTime" BO_ 801 1000;
BA_ "GenMsgSendType" BO_ 801 0;
BA_ "GenMsgCycleTime" BO_ 1349 33;
BA_ "GenMsgSendType" BO_ 1349 0;
BA_ "GenMsgCycleTime" BO_ 995 200;
BA_ "GenMsgSendType" BO_ 995 0;
BA_ "GenMsgCycleTime" BO_ 1066 100;
BA_ "GenMsgSendType" BO_ 1066 0;
BA_ "Confidence" SG_ 812 CC_logIndex 1;
BA_ "Confidence" SG_ 812 CC_activeConnectorID 0;
BA_ "Confidence" SG_ 812 CC_temperature1 0;
BA_ "Confidence" SG_ 812 CC_temperature2 0;
BA_ "Confidence" SG_ 812 CC_temperature3 0;
BA_ "Confidence" SG_ 812 CC_contactor1Closed 0;
BA_ "Confidence" SG_ 812 CC_contactor2Closed 0;
BA_ "Confidence" SG_ 812 CC_temperature4 0;
BA_ "Confidence" SG_ 812 CC_conn1Current 0;
BA_ "GenSigSNA" SG_ 812 CC_conn1Current "255";
BA_ "Confidence" SG_ 812 CC_conn2Current 0;
BA_ "GenSigSNA" SG_ 812 CC_conn2Current "255";
BA_ "Confidence" SG_ 812 CC_conn3Current 0;
BA_ "GenSigSNA" SG_ 812 CC_conn3Current "255";
BA_ "Confidence" SG_ 812 CC_conn4Current 0;
BA_ "GenSigSNA" SG_ 812 CC_conn4Current "255";
BA_ "Confidence" SG_ 812 CC_lifetimei2t 0;
BA_ "Confidence" SG_ 812 CC_lifetimeCtrCycles 0;
BA_ "Confidence" SG_ 812 CC_lifetimeCtrCyclesLoaded 0;
BA_ "Confidence" SG_ 812 CC_lifetimeAlertCount 0;
BA_ "Confidence" SG_ 812 CC_lifetimeThermalFoldbacks 0;
BA_ "Confidence" SG_ 812 CC_lifetimeAvgStartupTemp 0;
BA_ "Confidence" SG_ 2024 EPBR_infoIndex 1;
BA_ "Confidence" SG_ 2024 EPBR_infoBuildType 0;
BA_ "Confidence" SG_ 2024 EPBR_infoBuildConfigId 0;
BA_ "Confidence" SG_ 2024 EPBR_infoHardwareId 0;
BA_ "Confidence" SG_ 2024 EPBR_infoComponentId 0;
BA_ "Confidence" SG_ 2024 EPBR_infoPcbaId 0;
BA_ "Confidence" SG_ 2024 EPBR_infoAssemblyId 0;
BA_ "GenSigSNA" SG_ 2024 EPBR_infoAssemblyId "255";
BA_ "Confidence" SG_ 2024 EPBR_infoUsageId 0;
BA_ "Confidence" SG_ 2024 EPBR_infoSubUsageId 0;
BA_ "Confidence" SG_ 2024 EPBR_infoAppCrc 0;
BA_ "Confidence" SG_ 2024 EPBR_infoAppGitHash 0;
BA_ "Confidence" SG_ 2024 EPBR_infoBootGitHash 0;
BA_ "Confidence" SG_ 2024 EPBR_infoPlatformType 0;
BA_ "Confidence" SG_ 2024 EPBR_infoBootUdsProtoVersion 0;
BA_ "Confidence" SG_ 2024 EPBR_infoBootCrc 0;
BA_ "Confidence" SG_ 1914 HVP_log1HzIndex 1;
BA_ "Confidence" SG_ 1914 HVP_bmbAsicType 0;
BA_ "Confidence" SG_ 1914 HVP_shuntCurrentAuxLog 0;
BA_ "Confidence" SG_ 1914 HVP_pyroSquibResistance 0;
BA_ "GenSigSNA" SG_ 1914 HVP_pyroSquibResistance "65535";
BA_ "Confidence" SG_ 1914 HVP_shuntAsicChipXCoordinate 0;
BA_ "Confidence" SG_ 1914 HVP_shuntAsicChipYCoordinate 0;
BA_ "Confidence" SG_ 1914 HVP_hvilCalType 0;
BA_ "Confidence" SG_ 1914 HVP_gpioPcsDcdcPwmEnable 0;
BA_ "Confidence" SG_ 1914 HVP_gpioPcsChargePwmEnable 0;
BA_ "Confidence" SG_ 1914 HVP_gpioPcsEnable 0;
BA_ "Confidence" SG_ 1914 HVP_shuntAsicChipWaferNumber 0;
BA_ "Confidence" SG_ 1914 HVP_energyReserveMin 0;
BA_ "Confidence" SG_ 1914 HVP_energyReserveMax 0;
BA_ "Confidence" SG_ 1914 HVP_energyReserveAvg 0;
BA_ "Confidence" SG_ 676 PCS_chgPhATemp 0;
BA_ "GenSigSNA" SG_ 676 PCS_chgPhATemp "1025";
BA_ "Confidence" SG_ 676 PCS_chgPhBTemp 0;
BA_ "GenSigSNA" SG_ 676 PCS_chgPhBTemp "1025";
BA_ "Confidence" SG_ 676 PCS_chgPhCTemp 0;
BA_ "GenSigSNA" SG_ 676 PCS_chgPhCTemp "1025";
BA_ "Confidence" SG_ 676 PCS_dcdcTemp 0;
BA_ "GenSigSNA" SG_ 676 PCS_dcdcTemp "1025";
BA_ "Confidence" SG_ 676 PCS_ambientTemp 0;
BA_ "GenSigSNA" SG_ 676 PCS_ambientTemp "1025";
BA_ "Confidence" SG_ 676 PCS_dcdcBusbarTemp 0;
BA_ "GenSigSNA" SG_ 676 PCS_dcdcBusbarTemp "511";
BA_ "Confidence" SG_ 826 UI_ratedRange 0;
BA_ "Confidence" SG_ 826 UI_soe 0;
BA_ "Confidence" SG_ 826 UI_uSoe 0;
BA_ "Confidence" SG_ 801 VCFRONT_tempCoolantBatInlet 0;
BA_ "GenSigSNA" SG_ 801 VCFRONT_tempCoolantBatInlet "1023";
BA_ "Confidence" SG_ 801 VCFRONT_tempCoolantPTInlet 0;
BA_ "GenSigSNA" SG_ 801 VCFRONT_tempCoolantPTInlet "2047";
BA_ "Confidence" SG_ 801 VCFRONT_coolantLevel 0;
BA_ "Confidence" SG_ 801 VCFRONT_brakeFluidLevel 0;
BA_ "GenSigSNA" SG_ 801 VCFRONT_brakeFluidLevel "0";
BA_ "Confidence" SG_ 801 VCFRONT_tempAmbient 0;
BA_ "GenSigSNA" SG_ 801 VCFRONT_tempAmbient "0";
BA_ "Confidence" SG_ 801 VCFRONT_washerFluidLevel 0;
BA_ "GenSigSNA" SG_ 801 VCFRONT_washerFluidLevel "0";
BA_ "Confidence" SG_ 801 VCFRONT_tempAmbientFiltered 0;
BA_ "GenSigSNA" SG_ 801 VCFRONT_tempAmbientFiltered "0";
BA_ "Confidence" SG_ 801 VCFRONT_battSensorIrrational 0;
BA_ "Confidence" SG_ 801 VCFRONT_ptSensorIrrational 0;
BA_ "Confidence" SG_ 801 VCFRONT_sensorsCounter 0;
BA_ "Confidence" SG_ 801 VCFRONT_sensorsChecksum 0;
BA_ "Confidence" SG_ 1349 VCFRONT_systemStatusMuxIndex 1;
BA_ "Confidence" SG_ 1349 VCFRONT_systemStatusCounter 0;
BA_ "Confidence" SG_ 1349 VCFRONT_systemStatusChecksum 0;
BA_ "Confidence" SG_ 1349 VCFRONT_loadShedReason 0;
BA_ "Confidence" SG_ 1349 VCFRONT_VCRightEFuseLoadShedStag 0;
BA_ "SystemSignalLongSymbol" SG_ 1349 VCFRONT_VCRightEFuseLoadShedStag "VCFRONT_VCRightEFuseLoadShedStage";
BA_ "Confidence" SG_ 1349 VCFRONT_VCLeftEFuseLoadShedStage 0;
BA_ "Confidence" SG_ 1349 VCFRONT_DCDCSaturationLoadShedSt 0;
BA_ "SystemSignalLongSymbol" SG_ 1349 VCFRONT_DCDCSaturationLoadShedSt "VCFRONT_DCDCSaturationLoadShedStage";
BA_ "Confidence" SG_ 1349 VCFRONT_vehicleLoadShedStage 0;
BA_ "Confidence" SG_ 1349 VCFRONT_HVFaultVehicleLoadShedRe 0;
BA_ "SystemSignalLongSymbol" SG_ 1349 VCFRONT_HVFaultVehicleLoadShedRe "VCFRONT_HVFaultVehicleLoadShedRequest";
BA_ "Confidence" SG_ 1349 VCFRONT_postCrashVehicleLoadShed 0;
BA_ "SystemSignalLongSymbol" SG_ 1349 VCFRONT_postCrashVehicleLoadShed "VCFRONT_postCrashVehicleLoadShedActive";
BA_ "Confidence" SG_ 1349 VCFRONT_HVFaultVehicleLoadShedAc 0;
BA_ "SystemSignalLongSymbol" SG_ 1349 VCFRONT_HVFaultVehicleLoadShedAc "VCFRONT_HVFaultVehicleLoadShedActive";
BA_ "Confidence" SG_ 1349 VCFRONT_factoryVehicleLoadShedAc 0;
BA_ "SystemSignalLongSymbol" SG_ 1349 VCFRONT_factoryVehicleLoadShedAc "VCFRONT_factoryVehicleLoadShedActive";
BA_ "Confidence" SG_ 1349 VCFRONT_anyVehicleLoadShedActive 0;
BA_ "Confidence" SG_ 1349 VCFRONT_DIVehLoadShedActive 0;
BA_ "Confidence" SG_ 1349 VCFRONT_HVFaultLoadShedStateDBG 0;
BA_ "Confidence" SG_ 1349 VCFRONT_LVUnhealthyVehicleLoadSh 0;
BA_ "SystemSignalLongSymbol" SG_ 1349 VCFRONT_LVUnhealthyVehicleLoadSh "VCFRONT_LVUnhealthyVehicleLoadShedActive";
BA_ "Confidence" SG_ 1349 VCFRONT_loadShedStsCondenserFan 0;
BA_ "Confidence" SG_ 1349 VCFRONT_loadShedStsPTPump 0;
BA_ "Confidence" SG_ 1349 VCFRONT_loadShedMCUAudio 0;
BA_ "Confidence" SG_ 1349 VCFRONT_loadShedHVDownTriggerDBG 0;
BA_ "Confidence" SG_ 1349 VCFRONT_loadShedPCSSatTriggerDBG 0;
BA_ "Confidence" SG_ 1349 VCFRONT_loadShedStsBatteryPump 0;
BA_ "Confidence" SG_ 1349 VCFRONT_loadShedStsAPGlassHeater 0;
BA_ "Confidence" SG_ 1349 VCFRONT_loadShedStsMCUGraphics 0;
BA_ "Confidence" SG_ 1349 VCFRONT_IBSCurrentRMS_loadShed 0;
BA_ "Confidence" SG_ 1349 VCFRONT_loadShedAhLeakyBktCntDBG 0;
BA_ "Confidence" SG_ 1349 VCFRONT_loadShedPcs 0;
BA_ "Confidence" SG_ 1349 VCFRONT_loadShedGTWDownstrmRails 0;
BA_ "Confidence" SG_ 1349 VCFRONT_loadShedPCSMIATriggerDBG 0;
BA_ "Confidence" SG_ 1349 VCFRONT_loadShedTAS 0;
BA_ "Confidence" SG_ 1349 VCFRONT_loadShedBackStopBktCntDB 0;
BA_ "SystemSignalLongSymbol" SG_ 1349 VCFRONT_loadShedBackStopBktCntDB "VCFRONT_loadShedBackStopBktCntDBG";
BA_ "Confidence" SG_ 1349 VCFRONT_loadShedPCSLeakyBktCtDBG 0;
BA_ "Confidence" SG_ 1349 VCFRONT_loadShedUI 0;
BA_ "Confidence" SG_ 1349 VCFRONT_loadShedAutoPilot 0;
BA_ "Confidence" SG_ 995 VCRIGHT_brakeLightStatus 0;
BA_ "GenSigSNA" SG_ 995 VCRIGHT_brakeLightStatus "3";
BA_ "Confidence" SG_ 995 VCRIGHT_tailLightStatus 0;
BA_ "GenSigSNA" SG_ 995 VCRIGHT_tailLightStatus "3";
BA_ "Confidence" SG_ 995 VCRIGHT_turnSignalStatus 0;
BA_ "GenSigSNA" SG_ 995 VCRIGHT_turnSignalStatus "3";
BA_ "Confidence" SG_ 995 VCRIGHT_reverseLightStatus 0;
BA_ "GenSigSNA" SG_ 995 VCRIGHT_reverseLightStatus "3";
BA_ "Confidence" SG_ 995 VCRIGHT_rearFogLightStatus 0;
BA_ "GenSigSNA" SG_ 995 VCRIGHT_rearFogLightStatus "3";
BA_ "Confidence" SG_ 995 VCRIGHT_leftInteriorTrunkLightRe 0;
BA_ "SystemSignalLongSymbol" SG_ 995 VCRIGHT_leftInteriorTrunkLightRe "VCRIGHT_leftInteriorTrunkLightReq";
BA_ "Confidence" SG_ 995 VCRIGHT_audioCurrentSpikeDetecte 0;
BA_ "SystemSignalLongSymbol" SG_ 995 VCRIGHT_audioCurrentSpikeDetecte "VCRIGHT_audioCurrentSpikeDetected";
BA_ "Confidence" SG_ 1066 VCSEC_TPMSSensorState0 0;
BA_ "Confidence" SG_ 1066 VCSEC_TPMSRSSI0 0;
BA_ "Confidence" SG_ 1066 VCSEC_TPMSConnectionTypeCurrent0 0;
BA_ "Confidence" SG_ 1066 VCSEC_TPMSConnectionTypeDesired0 0;
BA_ "Confidence" SG_ 1066 VCSEC_TPMSSensorState1 0;
BA_ "Confidence" SG_ 1066 VCSEC_TPMSRSSI1 0;
BA_ "Confidence" SG_ 1066 VCSEC_TPMSConnectionTypeCurrent1 0;
BA_ "Confidence" SG_ 1066 VCSEC_TPMSConnectionTypeDesired1 0;
BA_ "Confidence" SG_ 1066 VCSEC_TPMSSensorState2 0;
BA_ "Confidence" SG_ 1066 VCSEC_TPMSRSSI2 0;
BA_ "Confidence" SG_ 1066 VCSEC_TPMSConnectionTypeCurrent2 0;
BA_ "Confidence" SG_ 1066 VCSEC_TPMSConnectionTypeDesired2 0;
BA_ "Confidence" SG_ 1066 VCSEC_TPMSSensorState3 0;
BA_ "Confidence" SG_ 1066 VCSEC_TPMSRSSI3 0;
BA_ "Confidence" SG_ 1066 VCSEC_TPMSConnectionTypeCurrent3 0;
BA_ "Confidence" SG_ 1066 VCSEC_TPMSConnectionTypeDesired3 0;
BA_ "Confidence" SG_ 1066 VCSEC_TPMSSensorPresence0 0;
BA_ "Confidence" SG_ 1066 VCSEC_TPMSSensorPresence1 0;
BA_ "Confidence" SG_ 1066 VCSEC_TPMSSensorPresence2 0;
BA_ "Confidence" SG_ 1066 VCSEC_TPMSSensorPresence3 0;
VAL_ 812 CC_logIndex 13 "Mux13" 12 "Mux12" 11 "Mux11" 10 "Mux10" 4 "Mux4" 3 "Mux3" 2 "Mux2" 1 "Mux1" 0 "Mux0" ;
VAL_ 812 CC_activeConnectorID 255 "SNA" ;
VAL_ 812 CC_temperature1 127 "SNA" ;
VAL_ 812 CC_temperature2 127 "SNA" ;
VAL_ 812 CC_temperature3 127 "SNA" ;
VAL_ 812 CC_contactor1Closed 3 "CC_CONTACTOR_SNA" 1 "CC_CONTACTOR_CLOSED" 0 "CC_CONTACTOR_OPEN" ;
VAL_ 812 CC_contactor2Closed 3 "CC_CONTACTOR_SNA" 1 "CC_CONTACTOR_CLOSED" 0 "CC_CONTACTOR_OPEN" ;
VAL_ 812 CC_temperature4 127 "SNA" ;
VAL_ 812 CC_conn1Current 255 "SNA" ;
VAL_ 812 CC_conn2Current 255 "SNA" ;
VAL_ 812 CC_conn3Current 255 "SNA" ;
VAL_ 812 CC_conn4Current 255 "SNA" ;
VAL_ 2024 EPBR_infoIndex 255 "END" 41 "SUBCOMPONENT14" 40 "SUBCOMPONENT13" 39 "SUBCOMPONENT12" 38 "SUBCOMPONENT11" 37 "SUBCOMPONENT10" 36 "SUBCOMPONENT9" 35 "SUBCOMPONENT8" 34 "SUBCOMPONENT7" 33 "SUBCOMPONENT6" 32 "SUBCOMPONENT5" 31 "SUBCOMPONENT4" 24 "SUBCOMPONENT3" 23 "SUBCOMPONENT2" 20 "UDS_PROTOCOL_BOOTCRC" 19 "VERSION_DEPRECATED" 18 "BOOTLOADER_GITHASH" 17 "APP_GITHASH" 16 "SUBCOMPONENT1" 15 "BOOTLOADER_CRC" 14 "BOOTLOADER_SVN" 13 "APP_CRC" 11 "PCBAID_ASSYID_USAGEID" 10 "BUILD_HWID_COMPONENTID" 9 "DEPRECATED_9" 8 "DEPRECATED_8" 7 "DEPRECATED_7" 6 "DEPRECATED_6" 5 "DEPRECATED_5" 4 "DEPRECATED_4" 3 "DEPRECATED_3" 2 "DEPRECATED_2" 1 "DEPRECATED_1" 0 "DEPRECATED_0" ;
VAL_ 2024 EPBR_infoBuildType 4 "INFO_MFG_BUILD" 3 "INFO_TRACEABLE_CI_BUILD" 2 "INFO_LOCAL_BUILD" 1 "INFO_PLATFORM_BUILD" 0 "INFO_UNKNOWN_BUILD" ;
VAL_ 2024 EPBR_infoAssemblyId 255 "ASSEMBLY_SNA" 1 "ASSEMBLY1" ;
VAL_ 1914 HVP_log1HzIndex 1 "Mux1" 0 "Mux0" ;
VAL_ 1914 HVP_bmbAsicType 3 "BQ796xx" 2 "ADBMS6830" 1 "LTC831" 0 "UNKNOWN" ;
VAL_ 1914 HVP_shuntCurrentAuxLog 8388000 "PACK_CURRENT_SNA" ;
VAL_ 1914 HVP_pyroSquibResistance 65535 "SNA" ;
VAL_ 1914 HVP_hvilCalType 2 "CAN" 1 "LV" 0 "UNKNOWN" ;
VAL_ 676 PCS_chgPhATemp -1023 "SNA" ;
VAL_ 676 PCS_chgPhBTemp -1023 "SNA" ;
VAL_ 676 PCS_chgPhCTemp -1023 "SNA" ;
VAL_ 676 PCS_dcdcTemp -1023 "SNA" ;
VAL_ 676 PCS_ambientTemp -1023 "SNA" ;
VAL_ 676 PCS_dcdcBusbarTemp 511 "SNA" ;
VAL_ 801 VCFRONT_tempCoolantBatInlet 1023 "SNA" ;
VAL_ 801 VCFRONT_tempCoolantPTInlet 2047 "SNA" ;
VAL_ 801 VCFRONT_coolantLevel 1 "FILLED" 0 "NOT_OK" ;
VAL_ 801 VCFRONT_brakeFluidLevel 2 "NORMAL" 1 "LOW" 0 "SNA" ;
VAL_ 801 VCFRONT_tempAmbient 0 "SNA" ;
VAL_ 801 VCFRONT_washerFluidLevel 2 "NORMAL" 1 "LOW" 0 "SNA" ;
VAL_ 801 VCFRONT_tempAmbientFiltered 0 "SNA" ;
VAL_ 1349 VCFRONT_systemStatusMuxIndex 2 "LOAD_SHED_STATUSES_AND_COMMANDS" 1 "ACTIVE_LOAD_SHED_REASONS" 0 "SYSTEM_DATA" ;
VAL_ 1349 VCFRONT_loadShedReason 256 "VCFRONT_LOAD_SHED_REASON_LV_HEALTH" 128 "VCFRONT_LOAD_SHED_REASON_PRECHARGE" 64 "VCFRONT_LOAD_SHED_REASON_CUSTOM" 32 "VCFRONT_LOAD_SHED_REASON_FACTORY" 16 "VCFRONT_LOAD_SHED_REASON_HV_FAULT" 8 "VCFRONT_LOAD_SHED_REASON_POST_CRASH" 4 "VCFRONT_LOAD_SHED_REASON_VCRIGHT_EFUSE_PROTECTION" 2 "VCFRONT_LOAD_SHED_REASON_VCLEFT_EFUSE_PROTECTION" 1 "VCFRONT_LOAD_SHED_REASON_DCDC_SATURATION" 0 "VCFRONT_LOAD_SHED_REASON_NONE" ;
VAL_ 1349 VCFRONT_VCRightEFuseLoadShedStag 31 "MAX" 0 "IDLE" ;
VAL_ 1349 VCFRONT_VCLeftEFuseLoadShedStage 31 "MAX" 0 "IDLE" ;
VAL_ 1349 VCFRONT_DCDCSaturationLoadShedSt 31 "MAX" 0 "IDLE" ;
VAL_ 1349 VCFRONT_vehicleLoadShedStage 3 "VEHICLE_LOADSHEDDING_STAGE_3" 2 "VEHICLE_LOADSHEDDING_STAGE_2" 1 "VEHICLE_LOADSHEDDING_STAGE_1" 0 "VEHICLE_LOADSHEDDING_STAGE_IDLE_OR_UNDEFINED" ;
VAL_ 1349 VCFRONT_HVFaultLoadShedStateDBG 3 "HV_FAULT_LOADSHED_SM_STATE_ACTIVE" 2 "HV_FAULT_LOADSHED_SM_STATE_BLOCKED" 1 "HV_FAULT_LOADSHED_SM_STATE_IDLE" 0 "HV_FAULT_LOADSHED_SM_STATE_INIT" ;
VAL_ 995 VCRIGHT_brakeLightStatus 3 "LIGHT_SNA" 2 "LIGHT_FAULT" 1 "LIGHT_ON" 0 "LIGHT_OFF" ;
VAL_ 995 VCRIGHT_tailLightStatus 3 "LIGHT_SNA" 2 "LIGHT_FAULT" 1 "LIGHT_ON" 0 "LIGHT_OFF" ;
VAL_ 995 VCRIGHT_turnSignalStatus 3 "LIGHT_SNA" 2 "LIGHT_FAULT" 1 "LIGHT_ON" 0 "LIGHT_OFF" ;
VAL_ 995 VCRIGHT_reverseLightStatus 3 "LIGHT_SNA" 2 "LIGHT_FAULT" 1 "LIGHT_ON" 0 "LIGHT_OFF" ;
VAL_ 995 VCRIGHT_rearFogLightStatus 3 "LIGHT_SNA" 2 "LIGHT_FAULT" 1 "LIGHT_ON" 0 "LIGHT_OFF" ;
VAL_ 1066 VCSEC_TPMSSensorState0 5 "SENSOR_WAIT_FOR_NEXT_ADV" 4 "SENSOR_DISCONNECTING" 3 "SENSOR_CONNECTED" 2 "SENSOR_WAIT_FOR_CONN" 1 "SENSOR_WAIT_FOR_ADV" 0 "SENSOR_NOT_PAIRED" ;
VAL_ 1066 VCSEC_TPMSConnectionTypeCurrent0 3 "CONNECTIONTYPE_FAST_SLAVE_LATENCY" 2 "CONNECTIONTYPE_UNKNOWN" 1 "CONNECTIONTYPE_SLOW" 0 "CONNECTIONTYPE_FAST" ;
VAL_ 1066 VCSEC_TPMSConnectionTypeDesired0 3 "CONNECTIONTYPE_FAST_SLAVE_LATENCY" 2 "CONNECTIONTYPE_UNKNOWN" 1 "CONNECTIONTYPE_SLOW" 0 "CONNECTIONTYPE_FAST" ;
VAL_ 1066 VCSEC_TPMSSensorState1 5 "SENSOR_WAIT_FOR_NEXT_ADV" 4 "SENSOR_DISCONNECTING" 3 "SENSOR_CONNECTED" 2 "SENSOR_WAIT_FOR_CONN" 1 "SENSOR_WAIT_FOR_ADV" 0 "SENSOR_NOT_PAIRED" ;
VAL_ 1066 VCSEC_TPMSConnectionTypeCurrent1 3 "CONNECTIONTYPE_FAST_SLAVE_LATENCY" 2 "CONNECTIONTYPE_UNKNOWN" 1 "CONNECTIONTYPE_SLOW" 0 "CONNECTIONTYPE_FAST" ;
VAL_ 1066 VCSEC_TPMSConnectionTypeDesired1 3 "CONNECTIONTYPE_FAST_SLAVE_LATENCY" 2 "CONNECTIONTYPE_UNKNOWN" 1 "CONNECTIONTYPE_SLOW" 0 "CONNECTIONTYPE_FAST" ;
VAL_ 1066 VCSEC_TPMSSensorState2 5 "SENSOR_WAIT_FOR_NEXT_ADV" 4 "SENSOR_DISCONNECTING" 3 "SENSOR_CONNECTED" 2 "SENSOR_WAIT_FOR_CONN" 1 "SENSOR_WAIT_FOR_ADV" 0 "SENSOR_NOT_PAIRED" ;
VAL_ 1066 VCSEC_TPMSConnectionTypeCurrent2 3 "CONNECTIONTYPE_FAST_SLAVE_LATENCY" 2 "CONNECTIONTYPE_UNKNOWN" 1 "CONNECTIONTYPE_SLOW" 0 "CONNECTIONTYPE_FAST" ;
VAL_ 1066 VCSEC_TPMSConnectionTypeDesired2 3 "CONNECTIONTYPE_FAST_SLAVE_LATENCY" 2 "CONNECTIONTYPE_UNKNOWN" 1 "CONNECTIONTYPE_SLOW" 0 "CONNECTIONTYPE_FAST" ;
VAL_ 1066 VCSEC_TPMSSensorState3 5 "SENSOR_WAIT_FOR_NEXT_ADV" 4 "SENSOR_DISCONNECTING" 3 "SENSOR_CONNECTED" 2 "SENSOR_WAIT_FOR_CONN" 1 "SENSOR_WAIT_FOR_ADV" 0 "SENSOR_NOT_PAIRED" ;
VAL_ 1066 VCSEC_TPMSConnectionTypeCurrent3 3 "CONNECTIONTYPE_FAST_SLAVE_LATENCY" 2 "CONNECTIONTYPE_UNKNOWN" 1 "CONNECTIONTYPE_SLOW" 0 "CONNECTIONTYPE_FAST" ;
VAL_ 1066 VCSEC_TPMSConnectionTypeDesired3 3 "CONNECTIONTYPE_FAST_SLAVE_LATENCY" 2 "CONNECTIONTYPE_UNKNOWN" 1 "CONNECTIONTYPE_SLOW" 0 "CONNECTIONTYPE_FAST" ;
VAL_ 1066 VCSEC_TPMSSensorPresence0 2 "PRESENT" 1 "NOT_PRESENT" 0 "NOT_PAIRED" ;
VAL_ 1066 VCSEC_TPMSSensorPresence1 2 "PRESENT" 1 "NOT_PRESENT" 0 "NOT_PAIRED" ;
VAL_ 1066 VCSEC_TPMSSensorPresence2 2 "PRESENT" 1 "NOT_PRESENT" 0 "NOT_PAIRED" ;
VAL_ 1066 VCSEC_TPMSSensorPresence3 2 "PRESENT" 1 "NOT_PRESENT" 0 "NOT_PAIRED" ;
